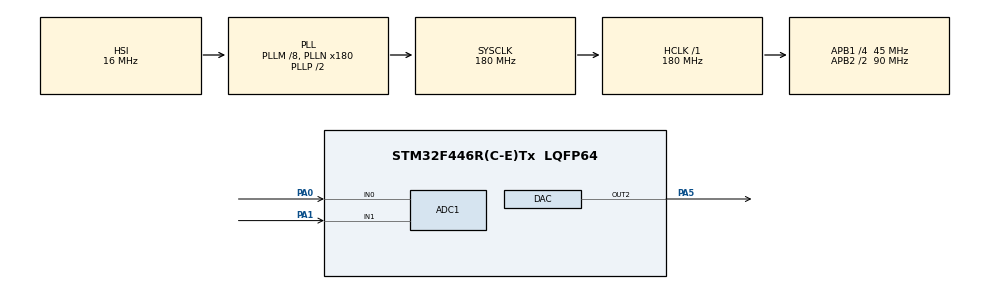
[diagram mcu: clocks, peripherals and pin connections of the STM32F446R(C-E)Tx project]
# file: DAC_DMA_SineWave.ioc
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ADC1.Channel-0\#ChannelRegularConversion=ADC_CHANNEL_0
ADC1.Channel-1\#ChannelRegularConversion=ADC_CHANNEL_1
ADC1.ContinuousConvMode=ENABLE
ADC1.DMAContinuousRequests=ENABLE
ADC1.NbrOfConversion=2
ADC1.NbrOfConversionFlag=1
ADC1.Rank-0\#ChannelRegularConversion=1
ADC1.Rank-1\#ChannelRegularConversion=2
ADC1.SamplingTime-0\#ChannelRegularConversion=ADC_SAMPLETIME_3CYCLES
ADC1.SamplingTime-1\#ChannelRegularConversion=ADC_SAMPLETIME_3CYCLES
ADC1.master=1
DAC.DAC_Trigger2=DAC_TRIGGER_T7_TRGO
Dma.ADC1.1.Direction=DMA_PERIPH_TO_MEMORY
Dma.ADC1.1.FIFOMode=DMA_FIFOMODE_DISABLE
Dma.ADC1.1.Instance=DMA2_Stream0
Dma.ADC1.1.MemDataAlignment=DMA_MDATAALIGN_WORD
Dma.ADC1.1.MemInc=DMA_MINC_ENABLE
Dma.ADC1.1.Mode=DMA_CIRCULAR
Dma.ADC1.1.PeriphDataAlignment=DMA_PDATAALIGN_WORD
Dma.ADC1.1.PeriphInc=DMA_PINC_DISABLE
Dma.ADC1.1.Priority=DMA_PRIORITY_VERY_HIGH
Dma.DAC2.0.Direction=DMA_MEMORY_TO_PERIPH
Dma.DAC2.0.FIFOMode=DMA_FIFOMODE_DISABLE
Dma.DAC2.0.Instance=DMA1_Stream6
Dma.DAC2.0.MemDataAlignment=DMA_MDATAALIGN_WORD
Dma.DAC2.0.MemInc=DMA_MINC_ENABLE
Dma.DAC2.0.Mode=DMA_CIRCULAR
Dma.DAC2.0.PeriphDataAlignment=DMA_PDATAALIGN_WORD
Dma.DAC2.0.PeriphInc=DMA_PINC_DISABLE
Dma.DAC2.0.Priority=DMA_PRIORITY_LOW
Dma.Request0=DAC2
Dma.Request1=ADC1
Mcu.Family=STM32F4
Mcu.Name=STM32F446R(C-E)Tx
Mcu.Package=LQFP64
NVIC.DMA1_Stream6_IRQn=true\:0\:0\:false\:false\:true\:false\:true\:true
NVIC.DMA2_Stream0_IRQn=true\:0\:0\:false\:false\:true\:false\:true\:true
NVIC.PriorityGroup=NVIC_PRIORITYGROUP_4
PA0-WKUP.Signal=ADCx_IN0
PA1.Signal=ADCx_IN1
PA13.Mode=Serial_Wire
PA13.Signal=SYS_JTMS-SWDIO
PA14.Mode=Serial_Wire
PA14.Signal=SYS_JTCK-SWCLK
PA5.Signal=COMP_DAC2_group
PC13.Mode=SYS_WakeUp1
PC13.Signal=SYS_WKUP1
ProjectManager.HeapSize=0x200
ProjectManager.StackSize=0x400
ProjectManager.TargetToolchain=STM32CubeIDE
RCC.AHBFreq_Value=180000000
RCC.APB1CLKDivider=RCC_HCLK_DIV4
RCC.APB1Freq_Value=45000000
RCC.APB1TimFreq_Value=90000000
RCC.APB2CLKDivider=RCC_HCLK_DIV2
RCC.APB2Freq_Value=90000000
RCC.APB2TimFreq_Value=180000000
RCC.CortexFreq_Value=180000000
RCC.HCLKFreq_Value=180000000
RCC.PLLM=8
RCC.PLLN=180
RCC.SYSCLKFreq_VALUE=180000000
RCC.SYSCLKSource=RCC_SYSCLKSOURCE_PLLCLK
RCC.USBFreq_Value=180000000
RCC.VCOOutputFreq_Value=360000000
SH.ADCx_IN0.0=ADC1_IN0,IN0
SH.ADCx_IN1.0=ADC1_IN1,IN1
SH.COMP_DAC2_group.0=DAC_OUT2,DAC_OUT2
TIM7.Period=4-1
TIM7.Prescaler=180-1
TIM7.TIM_MasterOutputTrigger=TIM_TRGO_UPDATE
VP_TIM7_VS_ClockSourceINT.Mode=Enable_Timer
board=custom

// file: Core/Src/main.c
/* USER CODE BEGIN Header */
/**
 ******************************************************************************
 * @file           : main.c
 * @brief          : Main program body
 ******************************************************************************
 * @attention
 *
 * Copyright (c) 2024 STMicroelectronics.
 * All rights reserved.
 *
 * This software is licensed under terms that can be found in the LICENSE file
 * in the root directory of this software component.
 * If no LICENSE file comes with this software, it is provided AS-IS.
 *
 ******************************************************************************
 */
/* USER CODE END Header */
#include "main.h"
#include "adc.h"
#include "dac.h"
#include "dma.h"
#include "tim.h"
#include "gpio.h"

/* USER CODE BEGIN Includes */

#include <math.h>

/* USER CODE END Includes */

/* USER CODE BEGIN PD */
#define SAMPLES 256 // Number of samples in one sine wave cycle
#define PI 3.14159265359
#define DAC_MAX_VALUE 4095 // 12-bit DAC resolution
#define ADC_RESOLUTION 4095 // 12-bit ADC resolution
#define BASE_FREQUENCY 1000 // Default frequency in Hz (1 kHz)
#define SYSTEM_CLOCK 180000000 // STM32F446RE at 180 MHz

/* USER CODE END PD */

/* USER CODE BEGIN PV */
uint32_t sine_wave[SAMPLES];
uint32_t adc_values[2];

/* USER CODE END PV */

void SystemClock_Config(void);
/* USER CODE BEGIN PFP */

void generate_sine_wave(uint16_t amplitude) {
	for (int i = 0; i < SAMPLES; i++) {
		sine_wave[i] = (uint16_t)((amplitude / 2) * (sin(2 * PI * i/SAMPLES) + 1));
	}
}

void adjustFrequency(TIM_HandleTypeDef *htim, uint32_t adc_value){

	uint32_t frequency = 500 + ((adc_value * 9500) / ADC_RESOLUTION);
	// Calculate new ARR value based on frequency and sample count
	uint32_t timer_frequency = frequency * SAMPLES;
	uint32_t arr_value = (SYSTEM_CLOCK / ((htim->Init.Prescaler + 1) * timer_frequency)) - 1;

	// Update ARR register for the timer
	__HAL_TIM_SET_AUTORELOAD(htim, arr_value);
}

// ADC DMA transfer complete callback
void HAL_ADC_ConvCpltCallback(ADC_HandleTypeDef *hadc) {
    if (hadc->Instance == ADC1) {
        // Adjust amplitude and regenerate sine wave
        uint16_t amplitude = (uint16_t)((adc_values[0] * DAC_MAX_VALUE) / ADC_RESOLUTION);
        generate_sine_wave(amplitude);

        // Adjust frequency dynamically
        adjustFrequency(&htim7, adc_values[1]);
    }
}

/* USER CODE END PFP */

int main(void)
{

  /* MCU Configuration--------------------------------------------------------*/

  /* Reset of all peripherals, Initializes the Flash interface and the Systick. */
  HAL_Init();

  /* Configure the system clock */
  SystemClock_Config();

  /* Initialize all configured peripherals */
  MX_GPIO_Init();
  MX_DMA_Init();
  MX_DAC_Init();
  MX_TIM7_Init();
  MX_ADC1_Init();
  /* USER CODE BEGIN 2 */

	generate_sine_wave(DAC_MAX_VALUE);

	HAL_TIM_Base_Start(&htim7);
	HAL_DAC_Start_DMA(&hdac, DAC_CHANNEL_2, sine_wave, SAMPLES, DAC_ALIGN_12B_R);

	// Start ADC in DMA mode
	HAL_ADC_Start_DMA(&hadc1, adc_values, 2);

  /* USER CODE END 2 */

  /* Infinite loop */
	while (1)
	{

	}
}

void SystemClock_Config(void)
{
  RCC_OscInitTypeDef RCC_OscInitStruct = {0};
  RCC_ClkInitTypeDef RCC_ClkInitStruct = {0};

  /** Configure the main internal regulator output voltage
  */
  __HAL_RCC_PWR_CLK_ENABLE();
  __HAL_PWR_VOLTAGESCALING_CONFIG(PWR_REGULATOR_VOLTAGE_SCALE1);

  /** Initializes the RCC Oscillators according to the specified parameters
  * in the RCC_OscInitTypeDef structure.
  */
  RCC_OscInitStruct.OscillatorType = RCC_OSCILLATORTYPE_HSI;
  RCC_OscInitStruct.HSIState = RCC_HSI_ON;
  RCC_OscInitStruct.HSICalibrationValue = RCC_HSICALIBRATION_DEFAULT;
  RCC_OscInitStruct.PLL.PLLState = RCC_PLL_ON;
  RCC_OscInitStruct.PLL.PLLSource = RCC_PLLSOURCE_HSI;
  RCC_OscInitStruct.PLL.PLLM = 8;
  RCC_OscInitStruct.PLL.PLLN = 180;
  RCC_OscInitStruct.PLL.PLLP = RCC_PLLP_DIV2;
  RCC_OscInitStruct.PLL.PLLQ = 2;
  RCC_OscInitStruct.PLL.PLLR = 2;
  if (HAL_RCC_OscConfig(&RCC_OscInitStruct) != HAL_OK)
  {
    Error_Handler();
  }

  /** Activate the Over-Drive mode
  */
  if (HAL_PWREx_EnableOverDrive() != HAL_OK)
  {
    Error_Handler();
  }

  /** Initializes the CPU, AHB and APB buses clocks
  */
  RCC_ClkInitStruct.ClockType = RCC_CLOCKTYPE_HCLK|RCC_CLOCKTYPE_SYSCLK
                              |RCC_CLOCKTYPE_PCLK1|RCC_CLOCKTYPE_PCLK2;
  RCC_ClkInitStruct.SYSCLKSource = RCC_SYSCLKSOURCE_PLLCLK;
  RCC_ClkInitStruct.AHBCLKDivider = RCC_SYSCLK_DIV1;
  RCC_ClkInitStruct.APB1CLKDivider = RCC_HCLK_DIV4;
  RCC_ClkInitStruct.APB2CLKDivider = RCC_HCLK_DIV2;

  if (HAL_RCC_ClockConfig(&RCC_ClkInitStruct, FLASH_LATENCY_5) != HAL_OK)
  {
    Error_Handler();
  }
}

void Error_Handler(void)
{
	__disable_irq();
	while (1)
	{
	}
}
